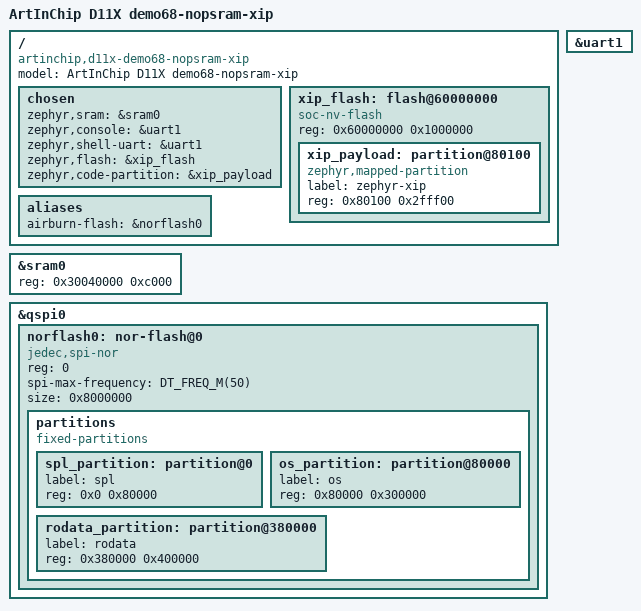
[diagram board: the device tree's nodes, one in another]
/*
 * SPDX-FileCopyrightText: Copyright (c) 2026 UltraSemi Technology Development Co., Ltd.
 * SPDX-License-Identifier: Apache-2.0
 */

/dts-v1/;

#include <artinchip/d11x.dtsi>

/* Luban-Lite c06865a38ca8bcffa337eee7b209651abacf45d6: target/d11x/demo68-nopsram-xip. */
/ {
	model = "ArtInChip D11X demo68-nopsram-xip";
	compatible = "artinchip,d11x-demo68-nopsram-xip";

	chosen {
		zephyr,sram = &sram0;
		zephyr,console = &uart1;
		zephyr,shell-uart = &uart1;
		zephyr,flash = &xip_flash;
		zephyr,code-partition = &xip_payload;
	};

	xip_flash: flash@60000000 {
		compatible = "soc-nv-flash";
		reg = <0x60000000 0x1000000>;
		#address-cells = <1>;
		#size-cells = <1>;
		ranges = <0 0x60000000 0x1000000>;

		/* OS starts at 0x80000; the AIC image header occupies 0x100. */
		xip_payload: partition@80100 {
			compatible = "zephyr,mapped-partition";
			label = "zephyr-xip";
			reg = <0x80100 0x2fff00>;
		};
	};
};

&sram0 {
	reg = <0x30040000 0xc000>;
};

&uart1 {
	status = "okay";
};

/* Bootloader-owned NOR metadata, not a runtime flash driver. */
/ {
	aliases {
		airburn-flash = &norflash0;
	};
};

&qspi0 {
	norflash0: nor-flash@0 {
		compatible = "jedec,spi-nor";
		reg = <0>;
		spi-max-frequency = <DT_FREQ_M(50)>;
		size = <0x8000000>; /* bits */
		partitions {
			compatible = "fixed-partitions";
			#address-cells = <1>;
			#size-cells = <1>;

			spl_partition: partition@0 {
				label = "spl";
				reg = <0x0 0x80000>;
			};

			os_partition: partition@80000 {
				label = "os";
				reg = <0x80000 0x300000>;
			};

			rodata_partition: partition@380000 {
				label = "rodata";
				reg = <0x380000 0x400000>;
			};
		};
	};
};
